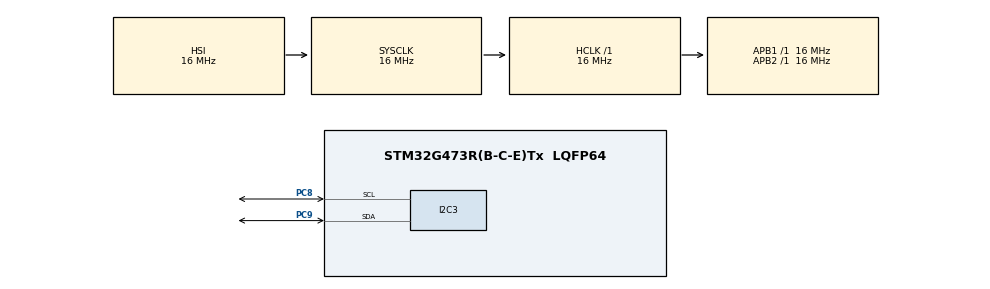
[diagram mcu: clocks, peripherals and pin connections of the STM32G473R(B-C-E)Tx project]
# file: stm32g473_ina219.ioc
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Mcu.Family=STM32G4
Mcu.Name=STM32G473R(B-C-E)Tx
Mcu.Package=LQFP64
NVIC.PriorityGroup=NVIC_PRIORITYGROUP_4
PC8.Mode=I2C
PC8.Signal=I2C3_SCL
PC9.Mode=I2C
PC9.Signal=I2C3_SDA
PF0-OSC_IN.Mode=HSE-External-Oscillator
PF0-OSC_IN.Signal=RCC_OSC_IN
PF1-OSC_OUT.Mode=HSE-External-Oscillator
PF1-OSC_OUT.Signal=RCC_OSC_OUT
ProjectManager.HeapSize=0x200
ProjectManager.StackSize=0x400
ProjectManager.TargetToolchain=STM32CubeIDE
RCC.AHBFreq_Value=16000000
RCC.APB1Freq_Value=16000000
RCC.APB1TimFreq_Value=16000000
RCC.APB2Freq_Value=16000000
RCC.APB2TimFreq_Value=16000000
RCC.CortexFreq_Value=16000000
RCC.EXTERNAL_CLOCK_VALUE=12288000
RCC.HCLKFreq_Value=16000000
RCC.HSE_VALUE=8000000
RCC.HSI48_VALUE=48000000
RCC.HSI_VALUE=16000000
RCC.LSE_VALUE=32768
RCC.SYSCLKFreq_VALUE=16000000
RCC.USBFreq_Value=64000000
RCC.VCOOutputFreq_Value=128000000
board=custom

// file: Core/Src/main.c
/* USER CODE BEGIN Header */
/**
 ******************************************************************************
 * @file           : main.c
 * @brief          : Main program body
 ******************************************************************************
 * @attention
 *
 * Copyright (c) 2023 STMicroelectronics.
 * All rights reserved.
 *
 * This software is licensed under terms that can be found in the LICENSE file
 * in the root directory of this software component.
 * If no LICENSE file comes with this software, it is provided AS-IS.
 *
 ******************************************************************************
 */
/* USER CODE END Header */
#include "main.h"

/* USER CODE BEGIN Includes */
#include "INA219.h"
/* USER CODE END Includes */

/* USER CODE BEGIN PTD */
// INA219.h
float ina219_currentDivider_mA;
float ina219_powerMultiplier_mW;
uint16_t ina219_calibrationValue;

/* USER CODE END PTD */

/* USER CODE BEGIN PM */

INA219_t ina219;

uint16_t vbus, vshunt, current;
/* USER CODE END PM */

I2C_HandleTypeDef hi2c3;

void SystemClock_Config(void);
static void MX_GPIO_Init(void);
static void MX_I2C3_Init(void);

int main(void)
{

	/* MCU Configuration--------------------------------------------------------*/

	/* Reset of all peripherals, Initializes the Flash interface and the Systick. */
	HAL_Init();

	/* Configure the system clock */
	SystemClock_Config();

	/* Initialize all configured peripherals */
	MX_GPIO_Init();
	MX_I2C3_Init();
	/* USER CODE BEGIN 2 */
	INA219_Init(&ina219, &hi2c3, INA219_ADDRESS);

	/* USER CODE END 2 */

	/* Infinite loop */
	while (1)
	{

		/* USER CODE BEGIN 3 */
		vbus = INA219_ReadBusVoltage(&ina219);
		vshunt = INA219_ReadShuntVolage(&ina219);
		current = INA219_ReadCurrent(&ina219);

	}
	/* USER CODE END 3 */
}

void SystemClock_Config(void)
{
	RCC_OscInitTypeDef RCC_OscInitStruct = {0};
	RCC_ClkInitTypeDef RCC_ClkInitStruct = {0};

	/** Configure the main internal regulator output voltage
	 */
	HAL_PWREx_ControlVoltageScaling(PWR_REGULATOR_VOLTAGE_SCALE1);

	/** Initializes the RCC Oscillators according to the specified parameters
	 * in the RCC_OscInitTypeDef structure.
	 */
	RCC_OscInitStruct.OscillatorType = RCC_OSCILLATORTYPE_HSI;
	RCC_OscInitStruct.HSIState = RCC_HSI_ON;
	RCC_OscInitStruct.HSICalibrationValue = RCC_HSICALIBRATION_DEFAULT;
	RCC_OscInitStruct.PLL.PLLState = RCC_PLL_NONE;
	if (HAL_RCC_OscConfig(&RCC_OscInitStruct) != HAL_OK)
	{
		Error_Handler();
	}

	/** Initializes the CPU, AHB and APB buses clocks
	 */
	RCC_ClkInitStruct.ClockType = RCC_CLOCKTYPE_HCLK|RCC_CLOCKTYPE_SYSCLK
			|RCC_CLOCKTYPE_PCLK1|RCC_CLOCKTYPE_PCLK2;
	RCC_ClkInitStruct.SYSCLKSource = RCC_SYSCLKSOURCE_HSI;
	RCC_ClkInitStruct.AHBCLKDivider = RCC_SYSCLK_DIV1;
	RCC_ClkInitStruct.APB1CLKDivider = RCC_HCLK_DIV1;
	RCC_ClkInitStruct.APB2CLKDivider = RCC_HCLK_DIV1;

	if (HAL_RCC_ClockConfig(&RCC_ClkInitStruct, FLASH_LATENCY_0) != HAL_OK)
	{
		Error_Handler();
	}
}

static void MX_I2C3_Init(void)
{

	hi2c3.Instance = I2C3;
	hi2c3.Init.Timing = 0x00303D5B;
	hi2c3.Init.OwnAddress1 = 0;
	hi2c3.Init.AddressingMode = I2C_ADDRESSINGMODE_7BIT;
	hi2c3.Init.DualAddressMode = I2C_DUALADDRESS_DISABLE;
	hi2c3.Init.OwnAddress2 = 0;
	hi2c3.Init.OwnAddress2Masks = I2C_OA2_NOMASK;
	hi2c3.Init.GeneralCallMode = I2C_GENERALCALL_DISABLE;
	hi2c3.Init.NoStretchMode = I2C_NOSTRETCH_DISABLE;
	if (HAL_I2C_Init(&hi2c3) != HAL_OK)
	{
		Error_Handler();
	}

	/** Configure Analogue filter
	 */
	if (HAL_I2CEx_ConfigAnalogFilter(&hi2c3, I2C_ANALOGFILTER_ENABLE) != HAL_OK)
	{
		Error_Handler();
	}

	/** Configure Digital filter
	 */
	if (HAL_I2CEx_ConfigDigitalFilter(&hi2c3, 0) != HAL_OK)
	{
		Error_Handler();
	}

}

static void MX_GPIO_Init(void)
{

	/* GPIO Ports Clock Enable */
	__HAL_RCC_GPIOF_CLK_ENABLE();
	__HAL_RCC_GPIOC_CLK_ENABLE();

}

void Error_Handler(void)
{
	__disable_irq();
	while (1)
	{
	}
}
